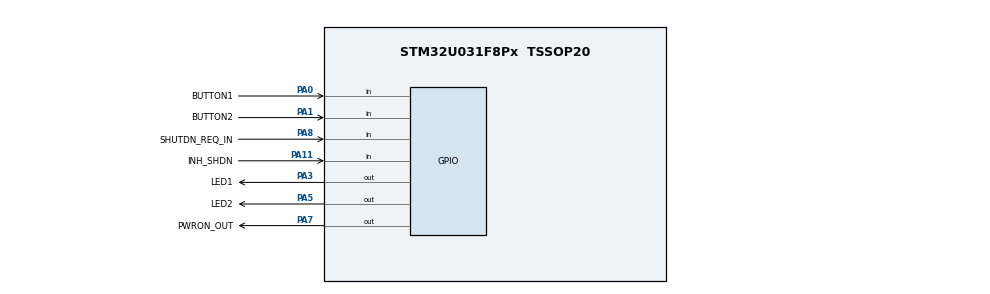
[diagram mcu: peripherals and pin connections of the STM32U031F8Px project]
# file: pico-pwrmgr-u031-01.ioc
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Mcu.Family=STM32U0
Mcu.Name=STM32U031F8Px
Mcu.Package=TSSOP20
NVIC.PriorityGroup=NVIC_PRIORITYGROUP_2
PA0-CK_IN.GPIO_Label=BUTTON1
PA0-CK_IN.GPIO_PuPd=GPIO_PULLUP
PA0-CK_IN.Signal=GPIO_Input
PA1.GPIO_Label=BUTTON2
PA1.GPIO_PuPd=GPIO_PULLUP
PA1.Signal=GPIO_Input
PA11\ [PA9].GPIO_Label=INH_SHDN
PA11\ [PA9].GPIO_PuPd=GPIO_PULLUP
PA11\ [PA9].Signal=GPIO_Input
PA13\ (SWDIO).Mode=Serial_Wire
PA13\ (SWDIO).Signal=DEBUG_JTMS-SWDIO
PA14\ (SWCLK).Mode=Serial_Wire
PA14\ (SWCLK).Signal=DEBUG_JTCK-SWCLK
PA14\ (SWCLK)__PB4__PB5__PB6.StandardMode=true
PA1__PA2.StandardMode=true
PA3.GPIO_Label=LED1
PA3.GPIO_ModeDefaultOutputPP=GPIO_MODE_OUTPUT_OD
PA3.GPIO_PuPd=GPIO_NOPULL
PA3.PinState=GPIO_PIN_SET
PA3.Signal=GPIO_Output
PA3__PA4.StandardMode=true
PA5.GPIO_Label=LED2
PA5.GPIO_ModeDefaultOutputPP=GPIO_MODE_OUTPUT_OD
PA5.GPIO_PuPd=GPIO_NOPULL
PA5.PinState=GPIO_PIN_SET
PA5.Signal=GPIO_Output
PA5__PA6.StandardMode=true
PA7.GPIO_Label=PWRON_OUT
PA7.Signal=GPIO_Output
PA7__PB0.StandardMode=true
PA8.GPIO_Label=SHUTDN_REQ_IN
PA8.GPIO_PuPd=GPIO_PULLUP
PA8.Signal=GPIO_Input
PB8__PB9.StandardMode=true
ProjectManager.HeapSize=0x200
ProjectManager.StackSize=0x400
ProjectManager.TargetToolchain=CMake
RCC.ADCFreq_Value=4000000
RCC.AHBFreq_Value=4000000
RCC.CortexFreq_Value=4000000
RCC.HCLKFreq_Value=4000000
RCC.HSE_VALUE=4000000
RCC.HSI48_VALUE=48000000
RCC.HSI_VALUE=16000000
RCC.LSE_VALUE=32768
RCC.MSI_VALUE=4000000
RCC.SYSCLKFreq_VALUE=4000000
RCC.SYSCLKSource=RCC_SYSCLKSOURCE_MSI
RCC.VCOOutputFreq_Value=64000000
VP_PWR_VS_SECSignals.Mode=Security/Privilege
board=custom

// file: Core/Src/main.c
/* USER CODE BEGIN Header */
/**
  ******************************************************************************
  * @file           : main.c
  * @brief          : Main program body
  ******************************************************************************
  * @attention
  *
  * Copyright (c) 2026 STMicroelectronics.
  * All rights reserved.
  *
  * This software is licensed under terms that can be found in the LICENSE file
  * in the root directory of this software component.
  * If no LICENSE file comes with this software, it is provided AS-IS.
  *
  ******************************************************************************
  */
/* USER CODE END Header */
#include "main.h"

/* USER CODE BEGIN Includes */

#include "qpn.h"  /* QP-nano */
#include "bsp.h"  /* Board Support Package */
#include "tasks.h"

/* USER CODE END Includes */

/* USER CODE BEGIN PV */

static QEvt l_testQueue[5];

/* QF_active[] array defines all active object control blocks --------------*/
QActiveCB const Q_ROM QF_active[] = {
    { (QActive *)0, (QEvt *)0, 0U },
    { (QActive *)&AO_Test,  l_testQueue,  Q_DIM(l_testQueue)  }
};

/* USER CODE END PV */

void SystemClock_Config(void);
static void MX_GPIO_Init(void);

int main(void)
{

  /* MCU Configuration--------------------------------------------------------*/

  /* Reset of all peripherals, Initializes the Flash interface and the Systick. */
  LL_APB1_GRP1_EnableClock(LL_APB1_GRP1_PERIPH_PWR);
  LL_APB1_GRP2_EnableClock(LL_APB1_GRP2_PERIPH_SYSCFG);

  /* System interrupt init*/
  NVIC_SetPriorityGrouping(NVIC_PRIORITYGROUP_2);

  /* SysTick_IRQn interrupt configuration */
  NVIC_SetPriority(SysTick_IRQn, NVIC_EncodePriority(NVIC_GetPriorityGrouping(),3, 0));

  /* USER CODE BEGIN Init */

    /* instantiate all AOs */
  Test_ctor(&AO_Test);

  QF_init(Q_DIM(QF_active)); /* initialize the QF-nano framework */
  BSP_init();      /* initialize the Board Support Package */

  /* USER CODE END Init */

  /* Configure the system clock */
  SystemClock_Config();

  /* Initialize all configured peripherals */
  MX_GPIO_Init();

  /* Infinite loop */
  /* USER CODE BEGIN WHILE */
  return QF_run(); /* transfer control to QF-nano */
    /* USER CODE END WHILE */

}

void SystemClock_Config(void)
{
  LL_FLASH_SetLatency(LL_FLASH_LATENCY_0);
  while(LL_FLASH_GetLatency() != LL_FLASH_LATENCY_0)
  {
  }

  LL_PWR_SetRegulVoltageScaling(LL_PWR_REGU_VOLTAGE_SCALE2);
  while (LL_PWR_IsActiveFlag_VOS() != 0)
  {
  }
  LL_RCC_MSI_Enable();

   /* Wait till MSI is ready */
  while(LL_RCC_MSI_IsReady() != 1)
  {
  }

  LL_RCC_MSI_EnableRangeSelection();
  LL_RCC_MSI_SetRange(LL_RCC_MSIRANGE_6);
  LL_RCC_SetSysClkSource(LL_RCC_SYS_CLKSOURCE_MSI);

   /* Wait till System clock is ready */
  while(LL_RCC_GetSysClkSource() != LL_RCC_SYS_CLKSOURCE_STATUS_MSI)
  {
  }

  LL_RCC_SetAHBPrescaler(LL_RCC_SYSCLK_DIV_1);
  LL_RCC_SetAPB1Prescaler(LL_RCC_APB1_DIV_1);

  LL_Init1msTick(4000000);

  LL_SetSystemCoreClock(4000000);
}

static void MX_GPIO_Init(void)
{
  LL_GPIO_InitTypeDef GPIO_InitStruct = {0};

  /* GPIO Ports Clock Enable */
  LL_IOP_GRP1_EnableClock(LL_IOP_GRP1_PERIPH_GPIOA);

  /**/
  LL_GPIO_SetOutputPin(GPIOA, LED1_Pin|LED2_Pin);

  /**/
  LL_GPIO_ResetOutputPin(PWRON_OUT_GPIO_Port, PWRON_OUT_Pin);

  /**/
  GPIO_InitStruct.Pin = BUTTON1_Pin|BUTTON2_Pin|SHUTDN_REQ_IN_Pin|INH_SHDN_Pin;
  GPIO_InitStruct.Mode = LL_GPIO_MODE_INPUT;
  GPIO_InitStruct.Pull = LL_GPIO_PULL_UP;
  LL_GPIO_Init(GPIOA, &GPIO_InitStruct);

  /**/
  GPIO_InitStruct.Pin = LED1_Pin|LED2_Pin;
  GPIO_InitStruct.Mode = LL_GPIO_MODE_OUTPUT;
  GPIO_InitStruct.Speed = LL_GPIO_SPEED_FREQ_LOW;
  GPIO_InitStruct.OutputType = LL_GPIO_OUTPUT_OPENDRAIN;
  GPIO_InitStruct.Pull = LL_GPIO_PULL_NO;
  LL_GPIO_Init(GPIOA, &GPIO_InitStruct);

  /**/
  GPIO_InitStruct.Pin = PWRON_OUT_Pin;
  GPIO_InitStruct.Mode = LL_GPIO_MODE_OUTPUT;
  GPIO_InitStruct.Speed = LL_GPIO_SPEED_FREQ_LOW;
  GPIO_InitStruct.OutputType = LL_GPIO_OUTPUT_PUSHPULL;
  GPIO_InitStruct.Pull = LL_GPIO_PULL_NO;
  LL_GPIO_Init(PWRON_OUT_GPIO_Port, &GPIO_InitStruct);

}

void Error_Handler(void)
{
  __disable_irq();
  while (1)
  {
  }
}
